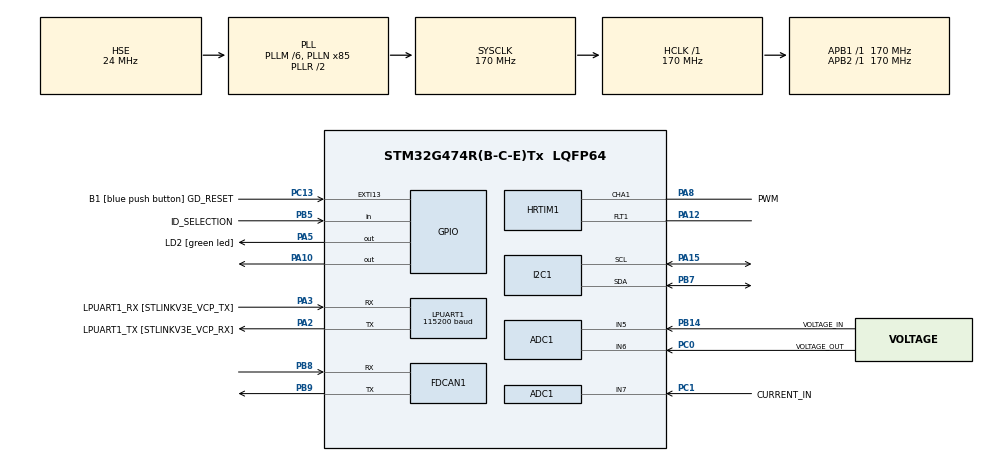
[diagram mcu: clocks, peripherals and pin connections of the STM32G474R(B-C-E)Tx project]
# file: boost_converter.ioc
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ADC1.Channel-10\#ChannelRegularConversion=ADC_CHANNEL_6
ADC1.Channel-11\#ChannelRegularConversion=ADC_CHANNEL_7
ADC1.Channel-7\#ChannelRegularConversion=ADC_CHANNEL_TEMPSENSOR_ADC1
ADC1.Channel-8\#ChannelRegularConversion=ADC_CHANNEL_VREFINT
ADC1.Channel-9\#ChannelRegularConversion=ADC_CHANNEL_5
ADC1.ClockPrescaler=ADC_CLOCK_ASYNC_DIV4
ADC1.ContinuousConvMode=DISABLE
ADC1.DMAContinuousRequests=ENABLE
ADC1.EOCSelection=ADC_EOC_SEQ_CONV
ADC1.EnableRegularConversion=ENABLE
ADC1.ExternalTrigConv=ADC_EXTERNALTRIG_T3_TRGO
ADC1.NbrOfConversion=5
ADC1.NbrOfConversionFlag=1
ADC1.OffsetNumber-10\#ChannelRegularConversion=ADC_OFFSET_NONE
ADC1.OffsetNumber-11\#ChannelRegularConversion=ADC_OFFSET_NONE
ADC1.OffsetNumber-7\#ChannelRegularConversion=ADC_OFFSET_NONE
ADC1.OffsetNumber-8\#ChannelRegularConversion=ADC_OFFSET_NONE
ADC1.OffsetNumber-9\#ChannelRegularConversion=ADC_OFFSET_NONE
ADC1.Overrun=ADC_OVR_DATA_PRESERVED
ADC1.OversamplingMode=ENABLE
ADC1.Rank-10\#ChannelRegularConversion=4
ADC1.Rank-11\#ChannelRegularConversion=5
ADC1.Rank-7\#ChannelRegularConversion=1
ADC1.Rank-8\#ChannelRegularConversion=2
ADC1.Rank-9\#ChannelRegularConversion=3
ADC1.Ratio=ADC_OVERSAMPLING_RATIO_8
ADC1.RightBitShift=ADC_RIGHTBITSHIFT_3
ADC1.SamplingTime-10\#ChannelRegularConversion=ADC_SAMPLETIME_640CYCLES_5
ADC1.SamplingTime-11\#ChannelRegularConversion=ADC_SAMPLETIME_640CYCLES_5
ADC1.SamplingTime-7\#ChannelRegularConversion=ADC_SAMPLETIME_92CYCLES_5
ADC1.SamplingTime-8\#ChannelRegularConversion=ADC_SAMPLETIME_92CYCLES_5
ADC1.SamplingTime-9\#ChannelRegularConversion=ADC_SAMPLETIME_640CYCLES_5
ADC1.master=1
Dma.ADC1.0.Direction=DMA_PERIPH_TO_MEMORY
Dma.ADC1.0.EventEnable=DISABLE
Dma.ADC1.0.Instance=DMA1_Channel1
Dma.ADC1.0.MemDataAlignment=DMA_MDATAALIGN_HALFWORD
Dma.ADC1.0.MemInc=DMA_MINC_ENABLE
Dma.ADC1.0.Mode=DMA_CIRCULAR
Dma.ADC1.0.PeriphDataAlignment=DMA_PDATAALIGN_HALFWORD
Dma.ADC1.0.PeriphInc=DMA_PINC_DISABLE
Dma.ADC1.0.Polarity=HAL_DMAMUX_REQ_GEN_RISING
Dma.ADC1.0.Priority=DMA_PRIORITY_MEDIUM
Dma.ADC1.0.RequestNumber=1
Dma.ADC1.0.SignalID=NONE
Dma.ADC1.0.SyncEnable=DISABLE
Dma.ADC1.0.SyncPolarity=HAL_DMAMUX_SYNC_NO_EVENT
Dma.ADC1.0.SyncRequestNumber=1
Dma.ADC1.0.SyncSignalID=NONE
Dma.Request0=ADC1
FDCAN1.AutoRetransmission=ENABLE
FDCAN1.CalculateBaudRateNominal=500000
FDCAN1.CalculateTimeBitNominal=2000
FDCAN1.CalculateTimeQuantumNominal=125.0
FDCAN1.ClockDivider=FDCAN_CLOCK_DIV1
FDCAN1.DataPrescaler=3
FDCAN1.DataSyncJumpWidth=1
FDCAN1.DataTimeSeg1=13
FDCAN1.DataTimeSeg2=2
FDCAN1.ExtFiltersNbr=8
FDCAN1.FrameFormat=FDCAN_FRAME_FD_NO_BRS
FDCAN1.Mode=FDCAN_MODE_NORMAL
FDCAN1.NominalPrescaler=3
FDCAN1.NominalSyncJumpWidth=1
FDCAN1.NominalTimeSeg1=13
FDCAN1.NominalTimeSeg2=2
FDCAN1.ProtocolException=ENABLE
FDCAN1.TransmitPause=DISABLE
FDCAN1.TxFifoQueueMode=FDCAN_TX_FIFO_OPERATION
HRTIM1.CompareUnit1-MasterTimer=__NULL
HRTIM1.CompareUnit1-Output_TA1=HRTIM_COMPAREUNIT_1
HRTIM1.CompareUnit2-MasterTimer=__NULL
HRTIM1.CompareValue1-Output_TA1=1250
HRTIM1.Configuration_TA=Waveform
HRTIM1.FaultEnable_Source1-Output_TA1=HRTIM_TIMFAULTENABLE_FAULT1
HRTIM1.Fault_Line1=HRTIM_FAULT_1
HRTIM1.GreaterCMP1_TA=HRTIM_TIMERGTCMP1_EQUAL
HRTIM1.NumberFaultEnable-Output_TA1=1
HRTIM1.NumberResetSource1-Output_TA1=1
HRTIM1.NumberSetSource1-Output_TA1=1
HRTIM1.Periode_MASTER=65503
HRTIM1.Periode_TA=4250
HRTIM1.PrescalerRatio_MASTER=HRTIM_PRESCALERRATIO_MUL32
HRTIM1.PrescalerRatio_TA=HRTIM_PRESCALERRATIO_DIV1
HRTIM1.ResetOutput1_Source1-Output_TA1=HRTIM_OUTPUTRESET_TIMCMP1
HRTIM1.SetOutput1_Source1-Output_TA1=HRTIM_OUTPUTSET_TIMPER
I2C1.Timing=0x40B285C2
LPUART1.BaudRate=115200
LPUART1.WordLength=UART_WORDLENGTH_8B
Mcu.Family=STM32G4
Mcu.Name=STM32G474R(B-C-E)Tx
Mcu.Package=LQFP64
NVIC.DMA1_Channel1_IRQn=true\:0\:0\:false\:false\:true\:false\:true\:true
NVIC.FDCAN1_IT0_IRQn=true\:0\:0\:false\:false\:true\:true\:true\:true
NVIC.HRTIM1_FLT_IRQn=true\:0\:0\:false\:false\:true\:true\:true\:true
NVIC.LPUART1_IRQn=true\:0\:0\:false\:false\:true\:true\:true\:true
NVIC.PriorityGroup=NVIC_PRIORITYGROUP_4
NVIC.TIM2_IRQn=true\:0\:0\:false\:false\:true\:true\:true\:true
NVIC.TIM3_IRQn=true\:0\:0\:false\:false\:true\:true\:true\:true
PA10.Signal=GPIO_Output
PA12.Mode=Fault_Enable1
PA12.Signal=HRTIM1_FLT1
PA13.GPIO_Label=T_SWDIO
PA13.Mode=Serial_Wire
PA13.Signal=SYS_JTMS-SWDIO
PA14.GPIO_Label=T_SWCLK
PA14.Mode=Serial_Wire
PA14.Signal=SYS_JTCK-SWCLK
PA15.Mode=I2C
PA15.Signal=I2C1_SCL
PA2.GPIO_Label=LPUART1_TX [STLINKV3E_VCP_RX]
PA2.Mode=Asynchronous
PA2.Signal=LPUART1_TX
PA3.GPIO_Label=LPUART1_RX [STLINKV3E_VCP_TX]
PA3.Mode=Asynchronous
PA3.Signal=LPUART1_RX
PA5.GPIO_Label=LD2 [green led]
PA5.Signal=GPIO_Output
PA8.GPIO_Label=PWM
PA8.Mode=Output_TA1
PA8.Signal=HRTIM1_CHA1
PB14.GPIO_Label=VOLTAGE_IN
PB14.Mode=IN5-Single-Ended
PB14.Signal=ADC1_IN5
PB3.GPIO_Label=T_SWO
PB3.Signal=SYS_JTDO-SWO
PB5.GPIO_Label=ID_SELECTION
PB5.Signal=GPIO_Input
PB7.Mode=I2C
PB7.Signal=I2C1_SDA
PB8-BOOT0.Mode=FDCAN_Activate
PB8-BOOT0.Signal=FDCAN1_RX
PB9.Mode=FDCAN_Activate
PB9.Signal=FDCAN1_TX
PC0.GPIO_Label=VOLTAGE_OUT
PC0.Mode=IN6-Single-Ended
PC0.Signal=ADC1_IN6
PC1.GPIO_Label=CURRENT_IN
PC1.Mode=IN7-Single-Ended
PC1.Signal=ADC1_IN7
PC13.GPIO_Label=B1 [blue push button] GD_RESET
PC13.Signal=GPXTI13
PC14-OSC32_IN.Mode=LSE-External-Oscillator
PC14-OSC32_IN.Signal=RCC_OSC32_IN
PC15-OSC32_OUT.Mode=LSE-External-Oscillator
PC15-OSC32_OUT.Signal=RCC_OSC32_OUT
PF0-OSC_IN.Mode=HSE-External-Oscillator
PF0-OSC_IN.Signal=RCC_OSC_IN
PF1-OSC_OUT.Mode=HSE-External-Oscillator
PF1-OSC_OUT.Signal=RCC_OSC_OUT
ProjectManager.HeapSize=0x200
ProjectManager.StackSize=0x400
ProjectManager.TargetToolchain=CMake
RCC.ADC12Freq_Value=170000000
RCC.ADC345Freq_Value=170000000
RCC.AHBFreq_Value=170000000
RCC.APB1Freq_Value=170000000
RCC.APB1TimFreq_Value=170000000
RCC.APB2Freq_Value=170000000
RCC.APB2TimFreq_Value=170000000
RCC.CortexFreq_Value=170000000
RCC.EXTERNAL_CLOCK_VALUE=12288000
RCC.FDCANCLockSelection=RCC_FDCANCLKSOURCE_HSE
RCC.HCLKFreq_Value=170000000
RCC.HSE_VALUE=24000000
RCC.HSI48_VALUE=48000000
RCC.HSI_VALUE=16000000
RCC.PLLM=RCC_PLLM_DIV6
RCC.PLLN=85
RCC.PLLSourceVirtual=RCC_PLLSOURCE_HSE
RCC.RTCClockSelection=RCC_RTCCLKSOURCE_LSE
RCC.SYSCLKFreq_VALUE=170000000
RCC.SYSCLKSource=RCC_SYSCLKSOURCE_PLLCLK
RCC.USBFreq_Value=170000000
RCC.VCOOutputFreq_Value=340000000
TIM2.PeriodNoDither=100-1
TIM2.Prescaler=170
TIM2.TIM_MasterOutputTrigger=TIM_TRGO_UPDATE
TIM3.PeriodNoDither=100-1
TIM3.Prescaler=17000
TIM3.TIM_MasterOutputTrigger=TIM_TRGO_UPDATE
VP_ADC1_TempSens_Input.Mode=IN-TempSens
VP_ADC1_Vref_Input.Mode=IN-Vrefint
VP_CORDIC_VS_CORDIC.Mode=CORDIC_Activate
VP_HRTIM1_VS_hrtimMasterTimerNoOutput.Mode=MasterTimer
VP_SYS_VS_DBSignals.Mode=DisableDeadBatterySignals
VP_TIM2_VS_ClockSourceINT.Mode=Internal
VP_TIM3_VS_ClockSourceINT.Mode=Internal
board=NUCLEO-G474RE

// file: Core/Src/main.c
/* USER CODE BEGIN Header */
/**
 ******************************************************************************
 * @file           : main.c
 * @brief          : Main program body
 ******************************************************************************
 * @attention
 *
 * Copyright (c) 2024 STMicroelectronics.
 * All rights reserved.
 *
 * This software is licensed under terms that can be found in the LICENSE file
 * in the root directory of this software component.
 * If no LICENSE file comes with this software, it is provided AS-IS.
 *
 ******************************************************************************
 */
/* USER CODE END Header */
#include "main.h"
#include "adc.h"
#include "cordic.h"
#include "dma.h"
#include "fdcan.h"
#include "hrtim.h"
#include "i2c.h"
#include "usart.h"
#include "tim.h"
#include "gpio.h"

/* USER CODE BEGIN Includes */
#include "boost_converter.h"
/* USER CODE END Includes */

void SystemClock_Config(void);

int main(void)
{

  /* MCU Configuration--------------------------------------------------------*/

  /* Reset of all peripherals, Initializes the Flash interface and the Systick. */
  HAL_Init();

  /* Configure the system clock */
  SystemClock_Config();

  /* Initialize all configured peripherals */
  MX_GPIO_Init();
  MX_DMA_Init();
  MX_LPUART1_UART_Init();
  MX_FDCAN1_Init();
  MX_HRTIM1_Init();
  MX_TIM3_Init();
  MX_I2C1_Init();
  MX_ADC1_Init();
  MX_CORDIC_Init();
  MX_TIM2_Init();
  /* USER CODE BEGIN 2 */

  int code = EVERT_BOOST_CONVERTER_main();
  if (code != 0)
  {
    Error_Handler();
  }
  /* USER CODE END 2 */

  /* Infinite loop */
  /* USER CODE BEGIN WHILE */
  while (1)
  {
    EVERT_BOOST_CONVERTER_loop();
    /* USER CODE END WHILE */

  }
}

void SystemClock_Config(void)
{
  RCC_OscInitTypeDef RCC_OscInitStruct = {0};
  RCC_ClkInitTypeDef RCC_ClkInitStruct = {0};

  /** Configure the main internal regulator output voltage
  */
  HAL_PWREx_ControlVoltageScaling(PWR_REGULATOR_VOLTAGE_SCALE1_BOOST);

  /** Initializes the RCC Oscillators according to the specified parameters
  * in the RCC_OscInitTypeDef structure.
  */
  RCC_OscInitStruct.OscillatorType = RCC_OSCILLATORTYPE_HSE;
  RCC_OscInitStruct.HSEState = RCC_HSE_ON;
  RCC_OscInitStruct.PLL.PLLState = RCC_PLL_ON;
  RCC_OscInitStruct.PLL.PLLSource = RCC_PLLSOURCE_HSE;
  RCC_OscInitStruct.PLL.PLLM = RCC_PLLM_DIV6;
  RCC_OscInitStruct.PLL.PLLN = 85;
  RCC_OscInitStruct.PLL.PLLP = RCC_PLLP_DIV2;
  RCC_OscInitStruct.PLL.PLLQ = RCC_PLLQ_DIV2;
  RCC_OscInitStruct.PLL.PLLR = RCC_PLLR_DIV2;
  if (HAL_RCC_OscConfig(&RCC_OscInitStruct) != HAL_OK)
  {
    Error_Handler();
  }

  /** Initializes the CPU, AHB and APB buses clocks
  */
  RCC_ClkInitStruct.ClockType = RCC_CLOCKTYPE_HCLK|RCC_CLOCKTYPE_SYSCLK
                              |RCC_CLOCKTYPE_PCLK1|RCC_CLOCKTYPE_PCLK2;
  RCC_ClkInitStruct.SYSCLKSource = RCC_SYSCLKSOURCE_PLLCLK;
  RCC_ClkInitStruct.AHBCLKDivider = RCC_SYSCLK_DIV1;
  RCC_ClkInitStruct.APB1CLKDivider = RCC_HCLK_DIV1;
  RCC_ClkInitStruct.APB2CLKDivider = RCC_HCLK_DIV1;

  if (HAL_RCC_ClockConfig(&RCC_ClkInitStruct, FLASH_LATENCY_4) != HAL_OK)
  {
    Error_Handler();
  }
}

/* USER CODE BEGIN 4 */

/**
 * @brief  Rx FIFO 0 callback.
 * @param  hfdcan: pointer to an FDCAN_HandleTypeDef structure that contains
 *         the configuration information for the specified FDCAN.
 * @param  RxFifo0ITs: indicates which Rx FIFO 0 interrupts are signalled.
 *         This parameter can be any combination of @arg FDCAN_Rx_Fifo0_Interrupts.
 * @retval None
 */
void HAL_FDCAN_RxFifo0Callback(FDCAN_HandleTypeDef *hfdcan, uint32_t RxFifo0ITs)
{
  EVERT_INVERTER_FDCAN_RxFifo0Callback(hfdcan, RxFifo0ITs);
}
/* USER CODE END 4 */

void Error_Handler(void)
{
  /* USER CODE BEGIN Error_Handler_Debug */
  /* User can add his own implementation to report the HAL error return state */
  EVERT_BOOST_CONVERTER_hal_error("Error Handler");
  /* USER CODE END Error_Handler_Debug */
}
